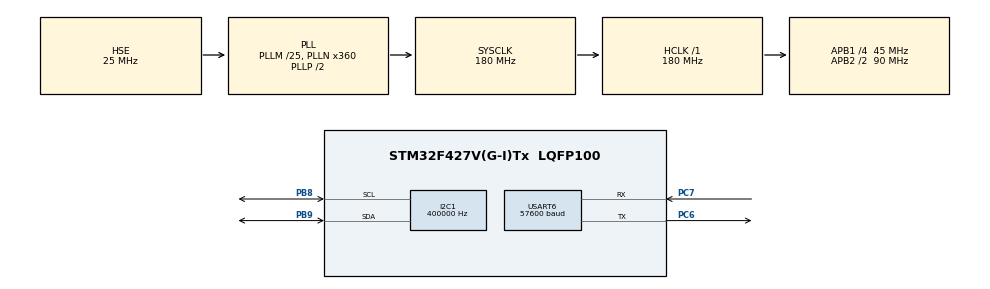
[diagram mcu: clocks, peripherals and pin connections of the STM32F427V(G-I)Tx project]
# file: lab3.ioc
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Mcu.Family=STM32F4
Mcu.Name=STM32F427V(G-I)Tx
Mcu.Package=LQFP100
NVIC.PriorityGroup=NVIC_PRIORITYGROUP_4
NVIC.USART6_IRQn=true\:0\:0\:false\:false\:true\:true\:true\:true
PA13.Mode=JTAG_5_pins
PA13.Signal=SYS_JTMS-SWDIO
PA14.Mode=JTAG_5_pins
PA14.Signal=SYS_JTCK-SWCLK
PA15.Mode=JTAG_5_pins
PA15.Signal=SYS_JTDI
PB3.Mode=JTAG_5_pins
PB3.Signal=SYS_JTDO-SWO
PB4.Mode=JTAG_5_pins
PB4.Signal=SYS_JTRST
PB8.Mode=I2C
PB8.Signal=I2C1_SCL
PB9.Mode=I2C
PB9.Signal=I2C1_SDA
PC6.Mode=Asynchronous
PC6.Signal=USART6_TX
PC7.Mode=Asynchronous
PC7.Signal=USART6_RX
PH0/OSC_IN.Mode=HSE-External-Oscillator
PH0/OSC_IN.Signal=RCC_OSC_IN
PH1/OSC_OUT.Mode=HSE-External-Oscillator
PH1/OSC_OUT.Signal=RCC_OSC_OUT
ProjectManager.HeapSize=0x200
ProjectManager.StackSize=0x800
ProjectManager.TargetToolchain=STM32CubeIDE
RCC.AHBFreq_Value=180000000
RCC.APB1CLKDivider=RCC_HCLK_DIV4
RCC.APB1Freq_Value=45000000
RCC.APB2CLKDivider=RCC_HCLK_DIV2
RCC.APB2Freq_Value=90000000
RCC.CortexFreq_Value=180000000
RCC.HCLKFreq_Value=180000000
RCC.HSE_VALUE=25000000
RCC.HSI_VALUE=16000000
RCC.LSE_VALUE=32768
RCC.PLLM=25
RCC.PLLN=360
RCC.PLLP=RCC_PLLP_DIV2
RCC.PLLQ=8
RCC.PLLSourceVirtual=RCC_PLLSOURCE_HSE
RCC.SYSCLKFreq_VALUE=180000000
RCC.SYSCLKSource=RCC_SYSCLKSOURCE_PLLCLK
RCC.VCOOutputFreq_Value=360000000
I2C1.ClockSpeed=400000
I2C1.DutyCycle=I2C_DUTYCYCLE_2
USART6.BaudRate=57600
USART6.VirtualMode=VM_ASYNC
board=custom

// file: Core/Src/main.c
/* USER CODE BEGIN Header */
/**
  ******************************************************************************
  * @file           : main.c
  * @brief          : Main program body
  ******************************************************************************
  * @attention
  *
  * Copyright (c) 2026 STMicroelectronics.
  * All rights reserved.
  *
  * This software is licensed under terms that can be found in the LICENSE file
  * in the root directory of this software component.
  * If no LICENSE file comes with this software, it is provided AS-IS.
  *
  ******************************************************************************
  */
/* USER CODE END Header */
#include "main.h"
#include "usart.h"
#include "gpio.h"

/* USER CODE BEGIN Includes */
#include "app.h"
#include "i2c.h"
/* USER CODE END Includes */

void SystemClock_Config(void);

int main(void)
{

  /* MCU Configuration--------------------------------------------------------*/

  /* Reset of all peripherals, Initializes the Flash interface and the Systick. */
  HAL_Init();

  /* Configure the system clock */
  SystemClock_Config();

  /* Initialize all configured peripherals */
  MX_GPIO_Init();
  MX_USART6_UART_Init();
  /* USER CODE BEGIN 2 */
  MX_I2C1_Init();
  app_init();
  /* USER CODE END 2 */

  /* Infinite loop */
  while (1)
  {

    /* USER CODE BEGIN 3 */
    app_poll();
  }
  /* USER CODE END 3 */
}

void SystemClock_Config(void)
{
  RCC_OscInitTypeDef RCC_OscInitStruct = {0};
  RCC_ClkInitTypeDef RCC_ClkInitStruct = {0};

  /** Configure the main internal regulator output voltage
  */
  __HAL_RCC_PWR_CLK_ENABLE();
  __HAL_PWR_VOLTAGESCALING_CONFIG(PWR_REGULATOR_VOLTAGE_SCALE1);

  /** Initializes the RCC Oscillators according to the specified parameters
  * in the RCC_OscInitTypeDef structure.
  */
  RCC_OscInitStruct.OscillatorType = RCC_OSCILLATORTYPE_HSE;
  RCC_OscInitStruct.HSEState = RCC_HSE_ON;
  RCC_OscInitStruct.PLL.PLLState = RCC_PLL_ON;
  RCC_OscInitStruct.PLL.PLLSource = RCC_PLLSOURCE_HSE;
  RCC_OscInitStruct.PLL.PLLM = 25;
  RCC_OscInitStruct.PLL.PLLN = 360;
  RCC_OscInitStruct.PLL.PLLP = RCC_PLLP_DIV2;
  RCC_OscInitStruct.PLL.PLLQ = 8;
  if (HAL_RCC_OscConfig(&RCC_OscInitStruct) != HAL_OK)
  {
    Error_Handler();
  }

  /** Activate the Over-Drive mode
  */
  if (HAL_PWREx_EnableOverDrive() != HAL_OK)
  {
    Error_Handler();
  }

  /** Initializes the CPU, AHB and APB buses clocks
  */
  RCC_ClkInitStruct.ClockType = RCC_CLOCKTYPE_HCLK|RCC_CLOCKTYPE_SYSCLK
                              |RCC_CLOCKTYPE_PCLK1|RCC_CLOCKTYPE_PCLK2;
  RCC_ClkInitStruct.SYSCLKSource = RCC_SYSCLKSOURCE_PLLCLK;
  RCC_ClkInitStruct.AHBCLKDivider = RCC_SYSCLK_DIV1;
  RCC_ClkInitStruct.APB1CLKDivider = RCC_HCLK_DIV4;
  RCC_ClkInitStruct.APB2CLKDivider = RCC_HCLK_DIV2;

  if (HAL_RCC_ClockConfig(&RCC_ClkInitStruct, FLASH_LATENCY_5) != HAL_OK)
  {
    Error_Handler();
  }
}

void Error_Handler(void)
{
  __disable_irq();
  while (1)
  {
  }
}
